# psoc4hv144k register map
Vendor: Infineon Technologies; Series: PSOC4HV144K; File version: 1.0
CPU: CM0PLUS r0p1, little endian, MPU, no FPU, VTOR, 2 interrupt priority bits
Registers are 32-bit, read-write, reset 0x0 unless marked. A register's access mark holds for its fields unless they carry their own. Offsets are from the block's base; [hi:lo] are bit positions; lines under a group give offsets from that group; {n}, {i} and the like mark numbered series; <NAME> marks a mode.

## PACSS (part 1 of 2) — Programmable Analog Channel Sub-System
Base 0x40300000
{0x0+0x10000*i} DCHAN[{i}] (i=0..3) group — Digital Channel Configuration
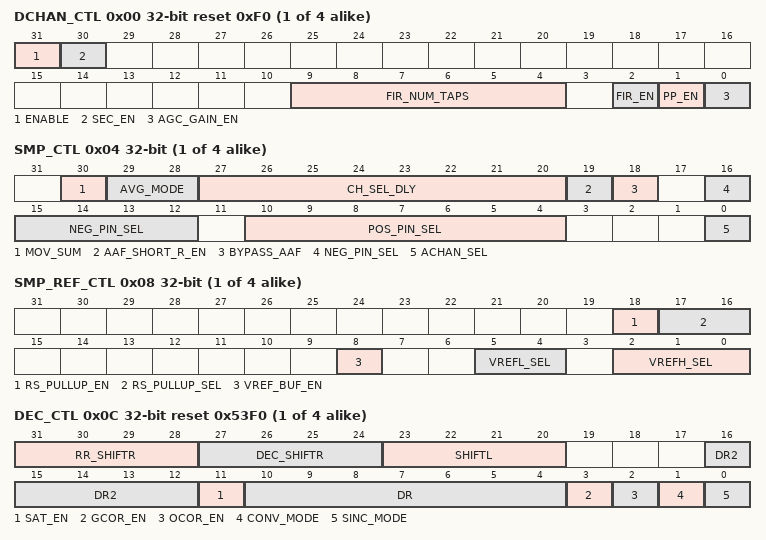
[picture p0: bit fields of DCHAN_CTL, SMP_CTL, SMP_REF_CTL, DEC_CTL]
  0x00 DCHAN_CTL reset 0xF0 — Digital Channel Control
    [31] ENABLE — Enable Digital Channel
    [30] SEC_EN — Secondary Channel Enable Use case is for diagnostic or temperature measurements. When a digital channel is set as secondary, when it is triggered, by a secondary trigger, the conversion of the channel pends until the next primary conversion completes. Secondary channels should always have a higher dchan index than the enabled primary channels associated with the same analog channel (ACHAN). For example if both dchan0 and dchan1 are using achan0, then dchan0 should never be set as a secondary channel. 0 - digital channel is configured as primary channel 1 - digital channel is configured as secondary channel
    [9:4] FIR_NUM_TAPS — FIR number of Taps. FIR_NUM_TAPS + 1 equals the numbers of Taps enabled in the FIR Filter
    [2] FIR_EN — FIR Enable 0 - Disabled 1 - Enabled
    [1] PP_EN — Post Processor Enable Enables all features of the post processor including the accumulated result register. When disabled the post processor is bypassed.
    [0] AGC_GAIN_EN — AGC Gain Enable 0 - Digital channel uses gain values from dchan configuration 1 - Digital channel uses gain values provided from AGC
  0x04 SMP_CTL — Sample Control
    [30] MOV_SUM — Moving Sum 0 - Off 1 - When AVG_MODE is enabled, no right shift occurs to divided result. Ex. If AVG_MODE=1 then the result is the sum of the last two samples. This register takes no affect when AVG_MODE=0.
    [29:28] AVG_MODE
    [27:20] CH_SEL_DLY — Channel Selection Delay. The value written to this field, plus 1, is the number of DSM clock cycles that will be inserted after the virtual channel configuration is loaded and before the decimator is started. Ex: write 7 for 8 clock cycles.
    [19] AAF_SHORT_R_EN — Automatically short the Anti-Aliasing Filter resistor during the channel selection delay. The expectation is that his will decrease the required settling time. Has no affect if BYPASS_AAF=1
    [18] BYPASS_AAF — Bypass the Anti-Aliasing Filter Open SW1, SW2, SW4, and close SW3 of the AAF during this channels conversion
    [16:12] NEG_PIN_SEL — Negative Pin Select
      0=NEG_PIN_SEL_VSSA (0x00 - vssa); 8=NEG_PIN_SEL_VSSA_K0 (0x08 - vssa_k0, unused (floating)); 9=NEG_PIN_SEL_VSSA_K1 (0x09 - vssa_k1, vrefl); 10=NEG_PIN_SEL_VSSA_K2 (0x0A - vssa_k2, srss_vss); 11=NEG_PIN_SEL_VSSA_K3 (0x0B - vssa_k3, vdiv_ret); 12=NEG_PIN_SEL_VSSA_K4 (0x0C - vssa_k4, vts_ret); 13=NEG_PIN_SEL_VSSA_K5 (0x0D - vssa_k5, vtint_ret); 14=NEG_PIN_SEL_VSSA_K6 (0x0E - vssa_k6, gpio0); 15=NEG_PIN_SEL_VSSA_K7 (0x0F - vssa_k7, gpio2); 16=NEG_PIN_SEL_RSL0 (0x10 - rsl0); 24=NEG_PIN_SEL_RSL1 (0x18 - rsl1); 26=NEG_PIN_SEL_AMUXA (0x1A - amuxbusa, if selected pos_pin_sel should be set to amuxbusb); 27=NEG_PIN_SEL_AMUXB (0x1B - amuxbusb, if selected pos_pin_sel should be set to amuxbusa)
    [10:4] POS_PIN_SEL — Positive Pin Select ( Sequencer controlled)
    [0] ACHAN_SEL — Analog Channel Selection Select which analog to use with this digital channel. 0 - Analog Channel 0 1 - Analog Channel 1
  0x08 SMP_REF_CTL — Sample Reference Control
    [18] RS_PULLUP_EN — Resistor Pull-up Enable
    [17:16] RS_PULLUP_SEL — Resistor Pull-up Select Based on the selection, the pin is pulled-up to VDDA via 4k-ohm (typ) resistor for open wire detection.
      0=RS_PULLUP_SEL_RSH1 (RSH[1] Pull-up Selected); 1=RS_PULLUP_SEL_RSH0 (RSH[0] Pull-up Selected); 2=RS_PULLUP_SEL_RSL1 (RSL[1] Pull-up Selected); 3=RS_PULLUP_SEL_RSL0 (RSL[0] Pull-up Selected)
    [8] VREF_BUF_EN — VREF Buffer Enable VREF_BUF_EN should only be used when a reference other than the default reference (HPBGR 0.1 percent reference) is used. When the HPBGR reference is used, the reference is provided directly from the HPBGR with the help from external cap for the transients. If this bit is set on a secondary channel, vref_buf_en for the assigned analog channel will be set once the secondary channel is pended to allow enough ramp up time of the VREFH buffer so that it is ready to sample once the secondary channel is ready to convert. The required ramp-up time of the VREFH buffer is 6 us, it is on the user to ensure the secondary channel is pended early enough to ensure this ramp-up time if the associated primary channel does not have this bit set.
    [5:4] VREFL_SEL — VREFL selection
      0=VREFL_SEL_VREFL; 1=VREFL_SEL_VSSA_SRSS (VSSA_SRSS); 2=VREFL_SEL_VSSA_KELVIN (VSSA_KELVIN); 3=VREFL_SEL_VTS_RET (VTS_RET)
    [2:0] VREFH_SEL — VREFH selection
      0=VREFH_SEL_VREFH_DIRECT (VREFH Direct (HPBGR)); 1=VREFH_SEL_VREFH_BUFFERED (VREFH Buffered (HPBGR)); 2=VREFH_SEL_SRSS (VREF SRSS); 3=VREFH_SEL_VTS_REF (VTS_REF); 4=VREFH_SEL_VDDA_DIV4 (VDDA/4); 5=VREF_HSEL_VDDA_DIV3 (VDDA/3)
  0x0C DEC_CTL reset 0x53F0 — Decimator Control
    [31:28] RR_SHIFTR — Rate Reducer Output Right Shift The maximum data path of the sinc2 rate reducer filter is 42-bits . This shift register is used to align the resolution down to 32-bits, otherwise the MSB bits will be truncated. To avoid truncation of relevant bits, the min value for this register should be: log2(qlev) + max(SHIFTL) + N*log2(DR +1) +2*log2(DR2+1) - DEC_SHIFTR - (32 - log2(U)) Where U = 1 for moving sum disabled, 2 for moving sum with avg mode=2 samples, and 4 for moving sum w/ avg mode =4 samples where DR2 is the values used in register programming (decimation ratios minus one)
    [27:24] DEC_SHIFTR — Decimator Output Right Shift The maximum data path of the sinc4 filter is 42-bits. This shift register is used to align the resolution down to 32-bits, otherwise the MSB bits will be truncated. To avoid truncation of relevant bits, the min value for this register should be: log2(qlev) + max(SHIFTL) + N*log2(DR +1) - (32 - log2(U)) Where U = 1 for moving sum disabled, 2 for moving sum with avg mode=2 samples, and 4 for moving sum w/ avg mode =4 samples where N = # of sinc stages (either 3 or 4 depending on sinc_mode field). In the equation above DR and DR2 are the values used in register programming (decimation ratios minus one)
    [23:20] SHIFTL — Shift Left (Scaler) Value for left shift amount of modulator input data. Supported values are 0 - 9. Using values 10-15 may result in a loss of data This register provides control information to the input (left) shifter. SHIFTL is a 4-bit field that sets the amount of left shift that the Modulator input will be shifted. Disturbing this field during a conversion will disturb the output value. This register should only be updated while the CIC filter is in the Standby state. Conversion results are unpredictable if these bits are changed while the filter is running. A read of this register produces the last value written to this register. This value is overridden by the Gain Level setting when DCHAN_CTL.AGC_GAIN_EN=1
    [16:12] DR2 — Decimation Ratio 2 DR2 is a 5-bit field that sets the decimation ratio (DR2+1) of the sinc2 rate reducer within the Decimator. The decimation ratio of the rate reducer minus one is the value that is programmed into this register. This field should not be changed during a conversion. DR2 must be less than DR/2. An example of some acceptable values for DR/DR2: Data Rate: DR+1: DR2+1: 48ksps 64 1 8ksps 64 6 4ksps 128 6 2ksps 128 12 1ksps 128 24
    [11] SAT_EN — Saturation Enable Controls saturation logic in the Decimator. When enabled, gain and offset calculations are held to the most positive or negative values, rather then wrapping around. Conversion results are unpredictable if this bit is changed while during a conversion. This bit is ignored if OCOR_EN and GCOR_EN are all 0. This feature is used to prevent wrap-around if the decimator is incorrectly configured. This bit should be set to 1 if OCOR_EN or GCOR_EN is set to 1.
    [10:4] DR — Decimation Ratio DR is an 7-bit field that sets the decimation ratio (DR+1) in the sinc3/sinc4 CIC filter. The decimation ratio minus one is the value that is programmed into this register. Changing this field during a conversion will disrupt the output value. Conversion results are unpredictable if these bits are changed while the filter is running. The suggested minimum value of DR is 0x3F. If a lower value is required, the minimum DR is determined by GVAL if gain is enabled. DR > (GCOR_COR.GVAL) * 2 when GCOR_EN is set to 1. An example of some acceptable values for DR/DR2: Data Rate: DR+1: DR2+1: 48ksps 64 1 8ksps 64 6 4ksps 128 6 2ksps 128 12 1ksps 128 24
    [3] GCOR_EN — Gain Correction Enable This bit controls the gain correction feature of the Decimator filter. The gain coefficient is programmed in the GCOR bits of the GAIN_COR register. Which bits in this 16-bit field that are valid is set in GVAL. Conversion results are unpredictable if this bit is changed while the filter is running. When this feature is enabled, the DR register field must be set to a value higher than 32 (worst case) for proper operation. See the DR register definition of cases where values less than 32 are allowed. This must be set to use DCHAN.GAIN_COR or GAIN_LVL_STRUCT.GAIN_COR. The value chosen, is based on DCHAN_CTL.AGC_GAIN_EN If OCOR_EN and GCOR_EN are both disabled this prevents the capability to loop back the data valid HW trigger of this channel and use it as the conversion start HW trigger of this channel. If either GCOR or OCOR is enabled this is allowed.
    [2] OCOR_EN — Offset Correction Enable This bit controls the offset correction feature of the Decimator filter. The offset value is programmed in the OCOR bits of the OFST_COR register. Conversion results are unpredictable if this bit is changed while the filter is running. This must be set to use DCHAN.OFST_COR or GAIN_LVL_STRUCT.OFST_COR, which one it chooses is based on DCHAN_CTL.AGC_GAIN_EN. If OCOR_EN and GCOR_EN are both disabled this prevents the capability to loop back the data valid HW trigger of this channel and use it as the conversion start HW trigger of this channel. If either GCOR or OCOR is enabled this is allowed.
    [1] CONV_MODE — Conversion Mode 0 - Incremental (Single Sample) 1 - Continuous This bit can be cleared during a continuous conversion to end the sample. In the expected use case: Primary channels should use Continuous, while secondary channels should be set to Incremental.
    [0] SINC_MODE — Decimator Sinc Mode 0 - Sinc3, Decimator is configured as a 3-state CIC decimation filter 1 - Sinc4, Decimator is configured as a 4-stage CIC decimation filter
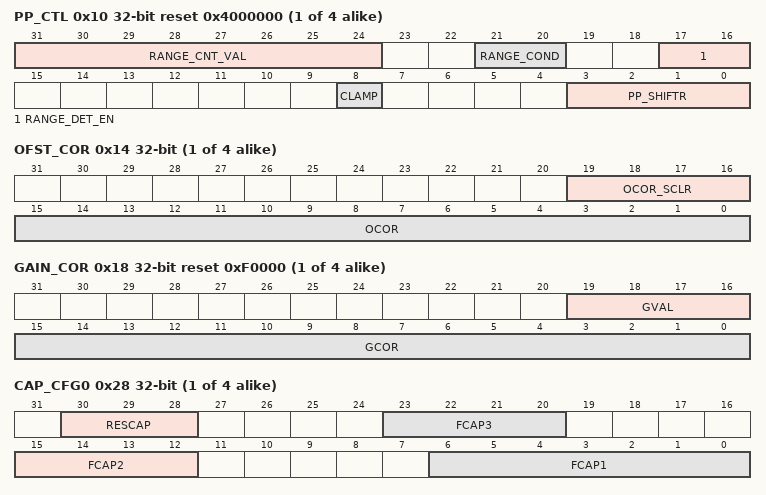
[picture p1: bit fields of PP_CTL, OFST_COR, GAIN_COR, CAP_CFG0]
  0x10 PP_CTL reset 0x4000000 — Post Processing Control
    [31:24] RANGE_CNT_VAL — Range Detection Count Value This register limits RANGE_INTR from asserting unless enough range detections have occurred. It is only used when RANGE_DET_EN=2'b10 mode. The range detection counter increments when a sample meets the range condition and decrements otherwise. When the range detection counter matches the RANGE_CNT_VAL the RANGE_INTR is asserted.
    [21:20] RANGE_COND — Range Condition Select 0 - result < RANGE_LOW 1 - RANGE_LOW <= result < RANGE_HIGH 2 - RANGE_HIGH <= result 3 - result < RANGE_LOW || RANGE_HIGH <= result
    [17:16] RANGE_DET_EN
    [8] CLAMP — Clamp 0 - Disabled (32-bit result) 1 - Clamps Result Data to 24-bits When enabled the max positive value will be clamped to 0x7FFFFF and the max negative value will be clamped to 0x800000.
    [3:0] PP_SHIFTR — Post Processor Right Shift Value for the amount of right shift for the input of the post processor (output of the FIR filter). The right shift operation is the first Post Processor operation. Processor. Functional values range from 0 to 15, 0 = no shift. This shift value will be based on the values of the FIR coefficients and the number of FIR taps. If the FIR is disabled, this value can be 0. If the FIR is enabled this shift value can be calculated by using the following: datapath bandwith: dp_bw = log2(qlev) + max(SHIFTL) + N*log2(DR +1) +2*log2(DR2+1) - DEC_SHIFTR - RR_SHIFTR FIR datapath adjustment: fir_dp_adj = log2(coeff[0] + coeff[1] + ... + coeff[n]) pp_shiftr = dp_bw + fir_adj -32
  0x14 OFST_COR — Offset Correction register
    [19:16] OCOR_SCLR — Decimator Offset Correction Coefficient Scaler OCOR_SCLR is the left shift amount to where the OCOR is applied to the decimation result. OCOR << OCOR_SCLR will be added to the decimation result.
    [15:0] OCOR — Decimator Offset Correction Coefficient OCOR is a 16-bit 2's compliment signed field that is the offset correction value used if the decimator Offset feature is enabled. This register may be written while the filter is running. OCOR<<OCOR_SCLR will be added to the decimation result.
  0x18 GAIN_COR reset 0xF0000 — Gain Correction register
    [19:16] GVAL — Number of valid bits minus one in Gain Coefficient registers GCOR GVAL is a 4-bit field that signifies to the HW how many bits of GCOR field are valid. The number of valid bits minus one should be written (0000b = 1 bit, 1111b = all 16 bits). Updates to this register will be ignored until the start of the next multiply. This register may be written while the filter is running. The valid field is measured from LSB (bit 0) up. Note that the HW always assumes the field specified by GVAL is left justified (starts at bit 0 of GCOR) and has a binary-point after the left-most digit. For example, if GVAL is programmed with a 7d, this means there are 8 valid bits in GCOR and they have the format x.xxxxxxxb. If GCOR holds the value 00000000 10100000b and GVAL is 7, only the low-order 8 bits are considered (10100000b) and the binary point is assumed after the left-most digit (1.0100000b). The multiply coefficient in the example would be 1.25d. Although a good explanation example, this isn't the most efficient way to multiply by 1.25d. Better would be GCOR holds the value 00000000 00000101b and GVAL is 2, which gives (1.01b). Another example: If it is desired to multiply by a gain coefficient of 0.125d (0.001b) then GCOR would be programmed with a value of 00000001b, GCORH with 00000000b and GVAL (GVAL) with 0011b - meaning there are 4 valid bits x.xxxb. The multiplier thus has a coefficient range of 1/(2^15) to 2.0-(1/(2^15)) in steps of 1/(2^15)
    [15:0] GCOR — Decimator Gain Correction Coefficient
  0x1C RANGE_LOW — Range Detect low value register.
    [31:0] RANGE_LOW — Low threshold for range detect
  0x20 RANGE_HIGH reset 0x7FFFFFFF — Range detect high value register.
    [31:0] RANGE_HIGH — High threshold for range detect
  0x24 PGA_GAIN_CTL — PGA Gain Control register
    [2:0] GAIN — PGA Gain setting of 1,2,4,8,16, 32 are supported This gain setting is overridden by AGC values if PACSS_CTL.AGC_EN=1 and DCHAN_CTL.AGC_GAIN_EN=1. Therefore the current value of the PGA gain can not be read from this register during AGC mode
      0=GAIN_1X (1x); 1=GAIN_2X (2x); 2=GAIN_4X (4x); 3=GAIN_8X (8x); 4=GAIN_16X (16x); 5=GAIN_32X (32x)
  0x28 CAP_CFG0 — Capacitor Configuration 0 register
    [30:28] RESCAP
    [23:20] FCAP3 — The third stage integrating capacitance
      0=FCAP3_100fF (100fF); 1=FCAP3_200fF (200fF); 2=FCAP3_300fF (300fF); 3=FCAP3_400fF (400fF); 4=FCAP3_500fF (500fF); 5=FCAP3_600fF (600fF); 6=FCAP3_700fF (700fF); 7=FCAP3_800fF (800fF); 8=FCAP3_900fF (900fF); 9=FCAP3_1000fF (1000fF); 10=FCAP3_1100fF (1100fF); 11=FCAP3_1200fF (1200fF); 12=FCAP3_1300fF (1300fF); 13=FCAP3_1400fF (1400fF); 14=FCAP3_1500fF (1500fF); 15=FCAP3_1600fF (1600fF)
    [15:12] FCAP2 — The second state integrating capacitance
      0=FCAP2_50fF (50fF); 1=FCAP2_100fF (100fF); 2=FCAP2_150fF (150fF); 3=FCAP2_200fF (200fF); 4=FCAP2_250fF (250fF); 5=FCAP2_300fF (300fF); 6=FCAP2_350fF (350fF); 7=FCAP2_400fF (400fF); 8=FCAP2_450fF (450fF); 9=FCAP2_500fF (500fF); 10=FCAP2_550fF (550fF); 11=FCAP2_600fF (600fF); 12=FCAP2_650fF (650fF); 13=FCAP2_700fF (700fF); 14=FCAP2_750fF (750fF); 15=FCAP2_800fF (800fF)
    [6:0] FCAP1 — binary weighted first stage integrating capacitance
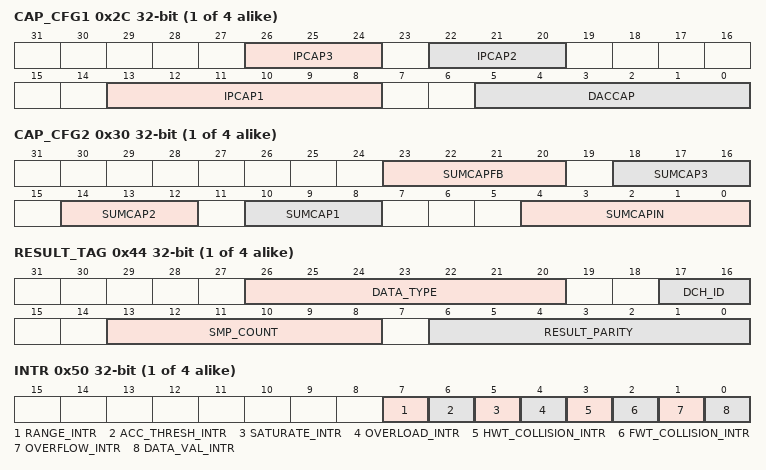
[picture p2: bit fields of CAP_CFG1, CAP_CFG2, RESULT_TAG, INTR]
  0x2C CAP_CFG1 — Capacitor Configuration 1 register
    [26:24] IPCAP3 — Binary weighted third stage input sampling capacitance
      0=IPCAP3_50fF (50fF); 1=IPCAP3_100fF (100fF); 2=IPCAP3_150fF (150fF); 3=IPCAP3_200fF (200fF); 4=IPCAP3_250fF (250fF); 5=IPCAP3_300fF (300fF); 6=IPCAP3_350fF (350fF); 7=IPCAP3_400fF (400fF)
    [22:20] IPCAP2 — Binary weighted second stage input sampling capacitance
      0=IPCAP2_50fF (50fF); 1=IPCAP2_100fF (100fF); 2=IPCAP2_150fF (150fF); 3=IPCAP2_200fF (200fF); 4=IPCAP2_250fF (250fF); 5=IPCAP2_300fF (300fF); 6=IPCAP2_350fF (350fF); 7=IPCAP2_400fF (400fF)
    [13:8] IPCAP1 — Binary weighted first stage input sampling capacitance
      0=IPCAP1_min (Min Value = 100 fF); 63=IPCAP1_max (Max Value = 6.4 pF); 1=IPCAP1_100fF (IPCAP1[0] set -> +100 fF); 2=IPCAP1_200fF (IPCAP1[1] set -> +200 fF); 4=IPCAP1_400fF (IPCAP1[2] set -> +400 fF); 8=IPCAP1_80fF (IPCAP1[3] set -> +800 fF); 16=IPCAP1_1600fF (IPCAP1[4] set -> +1600 fF); 32=IPCAP1_3200fF (IPCAP1[5] set -> +3200 fF)
    [5:0] DACCAP — Binary weighted first stage DAC capacitance
      0=DACCAP_min (Min Value = 96 fF); 63=DACCAP_max (Max Value = 6.4 pF); 1=DACCAP_96fF (DACCAP[0] set -> add 12*8= +96 fF); 2=DACCAP_192fF (DACCAP[1] set -> add 24*8= +192 fF); 4=DACCAP_400fF (DACCAP[2] set -> add 50*8= +400 fF); 8=DACCAP_800fF (DACCAP[3] set -> add 100*8= +800 fF); 16=DACCAP_1600fF (DACCAP[4] set -> add 200*8= +1600 fF); 32=DACCAP_3200fF (DACCAP[5] set -> add 400*8= +3200 fF)
  0x30 CAP_CFG2 — Capacitor Configuration 2 register
    [23:20] SUMCAPFB — The summer feedback capacitance
      0=SUMCAPFB_50fF (50fF); 1=SUMCAPFB_100fF (100fF); 2=SUMCAPFB_150fF (150fF); 3=SUMCAPFB_200fF (200fF); 4=SUMCAPFB_250fF (250fF); 5=SUMCAPFB_300fF (300fF); 6=SUMCAPFB_350fF (350fF); 7=SUMCAPFB_400fF (400fF); 8=SUMCAPFB_450fF (450fF); 9=SUMCAPFB_500fF (500fF); 10=SUMCAPFB_550fF (550fF); 11=SUMCAPFB_600fF (600fF); 12=SUMCAPFB_650fF (650fF); 13=SUMCAPFB_700fF (700fF); 14=SUMCAPFB_750fF (750fF); 15=SUMCAPFB_800fF (800fF)
    [18:16] SUMCAP3 — The summer capacitance that lies on the feed-forward path from the third integrator output (0fF to 350fF in 50fF step)
      0=SUMCAP3_50fF (50fF); 1=SUMCAP3_100fF (100fF); 2=SUMCAP3_150fF (150fF); 3=SUMCAP3_200fF (200fF); 4=SUMCAP3_250fF (250fF); 5=SUMCAP3_300fF (300fF); 6=SUMCAP3_350fF (350fF); 7=SUMCAP3_400fF (400fF)
    [14:12] SUMCAP2 — The summer capacitance that lies on the feed-forward path from the second integrator output (0fF to 350 in 50fF steps)
      0=SUMCAP2_50fF (50fF); 1=SUMCAP2_100fF (100fF); 2=SUMCAP2_150fF (150fF); 3=SUMCAP2_200fF (200fF); 4=SUMCAP2_250fF (250fF); 5=SUMCAP2_300fF (300fF); 6=SUMCAP2_350fF (350fF); 7=SUMCAP2_400fF (400fF)
    [10:8] SUMCAP1 — The summer capacitance that lies on the feed-forward path from the first integrator output (0fF to 350f, 50fF steps)
      0=SUMCAP1_50fF (50fF); 1=SUMCAP1_100fF (100fF); 2=SUMCAP1_150fF (150fF); 3=SUMCAP1_200fF (200fF); 4=SUMCAP1_250fF (250fF); 5=SUMCAP1_300fF (300fF); 6=SUMCAP1_350fF (350fF); 7=SUMCAP1_400fF (400fF)
    [4:0] SUMCAPIN — The summer capacitance that lies on the path where the input signal is summed (50fF to 1.6pF in 50f steps)
      0=SUMCAPIN_50fF (50fF); 1=SUMCAPIN_100fF (100fF); 2=SUMCAPIN_150fF (150fF); 3=SUMCAPIN_200fF (200fF); 4=SUMCAPIN_250fF (250fF); 5=SUMCAPIN_300fF (300fF); 6=SUMCAPIN_350fF (350fF); 7=SUMCAPIN_400fF (400fF); 8=SUMCAPIN_450fF (450fF); 9=SUMCAPIN_500fF (500fF); 10=SUMCAPIN_550fF (550fF); 11=SUMCAPIN_600fF (600fF); 12=SUMCAPIN_650fF (650fF); 13=SUMCAPIN_700fF (700fF); 14=SUMCAPIN_750fF (750fF); 15=SUMCAPIN_800fF (800fF); 16=SUMCAPIN_850fF (850fF); 17=SUMCAPIN_900fF (900fF); 18=SUMCAPIN_950fF (950fF); 19=SUMCAPIN_1000fF (1000fF); 20=SUMCAPIN_1050fF (1050fF); 21=SUMCAPIN_1100fF (1100fF); 22=SUMCAPIN_1150fF (1150fF); 23=SUMCAPIN_1200fF (1200fF); 24=SUMCAPIN_1250fF (1250fF); 25=SUMCAPIN_1300fF (1300fF); 26=SUMCAPIN_1350fF (1350fF); 27=SUMCAPIN_1400fF (1400fF); 28=SUMCAPIN_1450fF (1450fF); 29=SUMCAPIN_1500fF (1500fF); 30=SUMCAPIN_1550fF (1550fF); 31=SUMCAPIN_1600fF (1600fF)
  0x34 ACC_THRESH reset 0x7FFFFFFF — Accumulated Data Threshold
    [31:0] ACC_THRESH — Accumulated Threshold Once the ACC_RESULT register surpasses the threshold value written to this register the ACC_RESULT the ACC_THRESH_INTR is set. This value is signed and follows the two's-complement notation. If ACC_THRESH is set to a positive value, the ACC_RESULT must surpass the positive value of the ACC_THRESH to set the ACC_THRESH_INTR. If ACC_THRESH is set to a negative value, the ACC_RESULT must surpass the negative value ( a greater magnitude) of the ACC_THRESH to set the ACC_THRESH_INTR.
  0x40 RESULT ro — Channel result data register, updated at the end of each completed conversion
    [31:0] RESULT — Channel Result Data Register (signed) This is a two's complement value that is updated at the end of each completed conversion
  0x44 RESULT_TAG ro — Tag register associated and updated simultaneously with the RESULT register
    [26:20] DATA_TYPE — Result Data Type Represents the value of PACSS.DCHAN[]_SMP_CTL.POS_PIN_SEL.DATA_TYPE used during the conversion. Note that the DATA_TYPE is latched at the start of the conversion to ensure a constant input selection during the conversion, but is updated here at the end of conversion simultaneously with the RESULT register and the other RESULT_TAG fields.
    [17:16] DCH_ID — Digital Channel ID This field is a constant value of the digital channel(DCHAN) number this register is read from. The DCH_ID will be set immediately, before any sample completes.
    [13:8] SMP_COUNT — Sample Count This field can be used as a sequence ID, this field increments for every valid sample For example if moving average is enabled and set to 4. SMP_COUNT will equal one on the fourth sample, which will be the first data valid (interrupt). If moving average is disabled, the first sample will be valid. This value is set simultaneously with the result data. The count value is reset with PACSS_MMIO.PACSS_CTL.ENABLE=0 or DCHAN.DCHAN_CTL.ENABLE=0.
    [6:0] RESULT_PARITY — Result Parity (ECC Parity) This 7-bit ECC parity is generated from the 32-bit result data and is updated simultaneously with the result data.
  0x48 ACC_RESULT — Channel Accumulated result data register
    [31:0] ACC_RESULT — Accumulator Output result register. Write '0s' to clear. This register will only be updated if the post processor is enabled. This register must be manually cleared, it is not cleared after ACC_THRESH_INTR.
  0x50 INTR — Interrupt request register
    [7] RANGE_INTR — Range detect Interrupt: hardware sets this interrupt if the conversion result of that channel met the condition specified by the RANGE_LOW and RANGE_HIGH registers. Write with '1' to clear bit.
    [6] ACC_THRESH_INTR — Accumulated Threshold Interrupt: hardware sets this interrupt when the accumulated threshold value has been surpassed.
    [5] SATURATE_INTR — Saturate Interrupt: hardware sets this interrupt if a conversion result is prevented from overflowing in either the decimator or the post processor when PP_CTL.SAT_EN=1. Write with '1' to clear bit.
    [4] OVERLOAD_INTR — Overload Interrupt: hardware sets this interrupt for each channel if the modulator output is all zeros or all ones. This is an indication that the modulator is overloaded. Write with '1' to clear bit.
    [3] HWT_COLLISION_INTR — Hardware Trigger Collision Interrupt 0: hardware sets this interrupt when the HW trigger signal is asserted while the DSM is BUSY. Raising this interrupt is delayed to when the scan caused by the HW trigger has been completed, i.e. not when the preceding scan with which this trigger collided is completed. When this interrupt is set it implies that the channels were sampled later than was intended (jitter). Write with '1' to clear bit.
    [2] FWT_COLLISION_INTR — Firmware Trigger Collision Interrupt 0: hardware sets this interrupt when FW_TRIGGER is asserted while the DSM is BUSY. Raising this interrupt is delayed to when the scan caused by the FW_TRIGGER has been completed, i.e. not when the preceding scan with which this trigger collided is completed. When this interrupt is set it implies that the channels were sampled later than was intended (jitter). Write with '1' to clear bit.
    [1] OVERFLOW_INTR — Overflow Interrupt: hardware sets this interrupt when it sets a new DATA_VAL_INTR while that bit was not yet cleared by the firmware. Write with '1' to clear bit.
    [0] DATA_VAL_INTR — Data Valid Interrupt 0: hardware sets this interrupt after completing a scan of all the enabled channels. Write with '1' to clear bit.
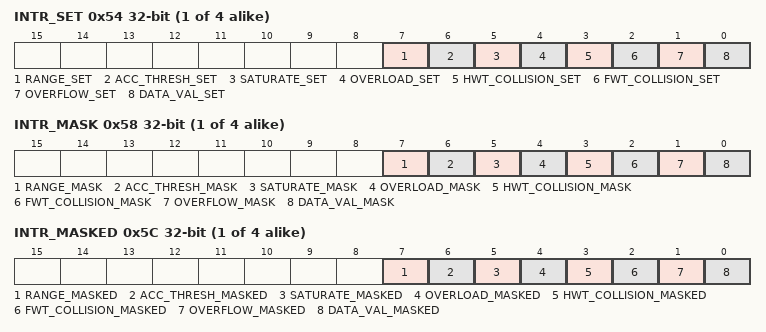
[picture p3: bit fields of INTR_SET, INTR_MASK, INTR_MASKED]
  0x54 INTR_SET — Interrupt set request register
    [7] RANGE_SET — Write with '1' to set corresponding bit in interrupt request register.
    [6] ACC_THRESH_SET — Write with '1' to set corresponding bit in interrupt request register.
    [5] SATURATE_SET — Write with '1' to set corresponding bit in interrupt request register.
    [4] OVERLOAD_SET — Write with '1' to set corresponding bit in interrupt request register.
    [3] HWT_COLLISION_SET — Write with '1' to set corresponding bit in interrupt request register.
    [2] FWT_COLLISION_SET — Write with '1' to set corresponding bit in interrupt request register.
    [1] OVERFLOW_SET — Write with '1' to set corresponding bit in interrupt request register.
    [0] DATA_VAL_SET — Write with '1' to set corresponding bit in interrupt request register.
  0x58 INTR_MASK — Interrupt mask register
    [7] RANGE_MASK — Mask bit for corresponding bit in interrupt request register.
    [6] ACC_THRESH_MASK — Mask bit for corresponding bit in interrupt request register.
    [5] SATURATE_MASK — Mask bit for corresponding bit in interrupt request register.
    [4] OVERLOAD_MASK — Mask bit for corresponding bit in interrupt request register.
    [3] HWT_COLLISION_MASK — Mask bit for corresponding bit in interrupt request register.
    [2] FWT_COLLISION_MASK — Mask bit for corresponding bit in interrupt request register.
    [1] OVERFLOW_MASK — Mask bit for corresponding bit in interrupt request register.
    [0] DATA_VAL_MASK — Mask bit for corresponding bit in interrupt request register.
  0x5C INTR_MASKED ro — Interrupt masked request register
    [7] RANGE_MASKED — Logical and of corresponding request and mask bits.
    [6] ACC_THRESH_MASKED — Logical and of corresponding request and mask bits.
    [5] SATURATE_MASKED — Logical and of corresponding request and mask bits.
    [4] OVERLOAD_MASKED — Logical and of corresponding request and mask bits.
    [3] HWT_COLLISION_MASKED — Logical and of corresponding request and mask bits.
    [2] FWT_COLLISION_MASKED — Logical and of corresponding request and mask bits.
    [1] OVERFLOW_MASKED — Logical and of corresponding request and mask bits.
    [0] DATA_VAL_MASKED — Logical and of corresponding request and mask bits.
  0x60 STATUS ro — Status registesr
    [0] OVERLOAD_CAUSE — To be read after OVERLOAD_INTR issues. If read returns 0, overload is due to all 0s. If read returns 1, overload is due to all 1s
  {0x100+0x10*j} FCFG[{j}] (j=0..63) group — FIR Configuration
    0x00 COEF reset not defined — Coefficient Value
      [15:0] COEF — FIR Coefficient Value The coefficient values can range from -1+1/(2^15) to 1-1/(2^15) with a resolution of 1/(2^15). The coefficient uses twos-complement notation and the decimal point is fixed to the right of the most significant bit. Examples: -0.25 = 0xE000 and 0.25 = 0x2000 Note: The Coefficient values are stored in SRAM, not registers. They are not initialized during a reset. They also cannot be accessed during a conversion.
    0x08 TAP reset not defined — Tap Value
      [31:0] TAP — Tap value, Witten by hardware readable by software. Note: The TAP values are stored in SRAM, not registers. They are not initialized during a reset. They also cannot be accessed during a conversion.

## Notices in the file
(c) (2016-2025), Cypress Semiconductor Corporation (an Infineon company)
or an affiliate of Cypress Semiconductor Corporation.
SPDX-License-Identifier: Apache-2.0
Licensed under the Apache License, Version 2.0 (the "License");
you may not use this file except in compliance with the License.
You may obtain a copy of the License at
http://www.apache.org/licenses/LICENSE-2.0
Unless required by applicable law or agreed to in writing, software
distributed under the License is distributed on an "AS IS" BASIS,
WITHOUT WARRANTIES OR CONDITIONS OF ANY KIND, either express or implied.
See the License for the specific language governing permissions and
limitations under the License.
